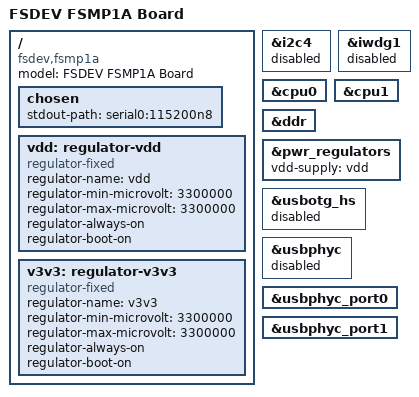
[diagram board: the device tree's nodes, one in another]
// SPDX-License-Identifier: (GPL-2.0+ OR BSD-3-Clause)
/*
 * Copyright (C) 2019-2023, STMicroelectronics - All Rights Reserved
 * Author: Alexandre Torgue <alexandre.torgue@st.com> for STMicroelectronics.
 */

/dts-v1/;

#include "stm32mp157.dtsi"
#include "stm32mp15-pinctrl.dtsi"
#include "stm32mp15xxac-pinctrl.dtsi"
#include "stm32mp15xx-dkx.dtsi"

/ {
	model = "FSDEV FSMP1A Board";
	compatible = "fsdev,fsmp1a", "st,stm32mp157";

	chosen {
		stdout-path = "serial0:115200n8";
	};

	/*
	 * Board is discrete power supplied: no STPMIC1. Only VDD is described
	 * here, it is read back by stm32mp1_syscfg.c to decide whether the
	 * high speed low voltage pad mode may be enabled (VDD < 2.7V).
	 */
	vdd: regulator-vdd {
		compatible = "regulator-fixed";
		regulator-name = "vdd";
		regulator-min-microvolt = <3300000>;
		regulator-max-microvolt = <3300000>;
		regulator-always-on;
		regulator-boot-on;
	};

	/* SDMMC1 card power (&sdmmc1 vmmc-supply) */
	v3v3: regulator-v3v3 {
		compatible = "regulator-fixed";
		regulator-name = "v3v3";
		regulator-min-microvolt = <3300000>;
		regulator-max-microvolt = <3300000>;
		regulator-always-on;
		regulator-boot-on;
	};
};

/*
 * The PMIC node must be deleted, not disabled: in BL2 dt_pmic_status() returns
 * DT_SECURE as soon as a "st,stpmic1" node is found, whatever its status.
 */
/delete-node/ &pmic;

&i2c4 {
	status = "disabled";
};

&iwdg1 {
	status = "disabled";
};

/* Drop the now dangling references to the STPMIC1 regulators. */
&cpu0 {
	/delete-property/ cpu-supply;
};

&cpu1 {
	/delete-property/ cpu-supply;
};

&ddr {
	/delete-property/ vdd-supply;
	/delete-property/ vtt-supply;
	/delete-property/ vref-supply;
};

&pwr_regulators {
	vdd-supply = <&vdd>;
	/delete-property/ vdd_3v3_usbfs-supply;
};

/* No USB boot / DFU support wanted on this board. */
&usbotg_hs {
	status = "disabled";
};

&usbphyc {
	status = "disabled";
};

&usbphyc_port0 {
	/delete-property/ phy-supply;
};

&usbphyc_port1 {
	/delete-property/ phy-supply;
};
